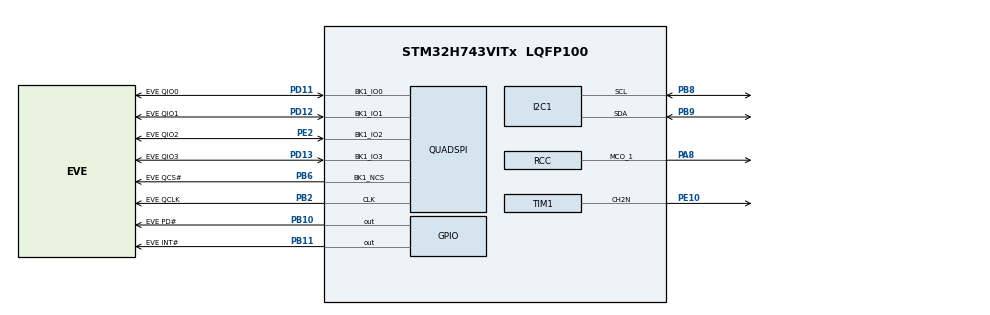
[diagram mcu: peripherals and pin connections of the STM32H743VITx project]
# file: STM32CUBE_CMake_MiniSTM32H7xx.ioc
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CORTEX_M7.AccessPermission-Cortex_Memory_Protection_Unit_Region0_Settings=MPU_REGION_PRIV_RO
CORTEX_M7.BaseAddress-Cortex_Memory_Protection_Unit_Region0_Settings=0x08000000
CORTEX_M7.Enable-Cortex_Memory_Protection_Unit_Region0_Settings=MPU_REGION_ENABLE
CORTEX_M7.IsCacheable-Cortex_Memory_Protection_Unit_Region0_Settings=MPU_ACCESS_CACHEABLE
CORTEX_M7.MPU_Control=MPU_PRIVILEGED_DEFAULT
CORTEX_M7.Size-Cortex_Memory_Protection_Unit_Region0_Settings=MPU_REGION_SIZE_2MB
CORTEX_M7.TypeExtField-Cortex_Memory_Protection_Unit_Region0_Settings=MPU_TEX_LEVEL1
I2C1.I2C_Fall_Time=10
I2C1.I2C_Rise_Time=100
I2C1.Timing=0xA010151E
Mcu.Family=STM32H7
Mcu.Name=STM32H743VITx
Mcu.Package=LQFP100
NVIC.PriorityGroup=NVIC_PRIORITYGROUP_4
NVIC.TIM16_IRQn=true\:0\:0\:false\:false\:true\:true\:true\:true
PA13\ (JTMS/SWDIO).Mode=Trace_Asynchronous_SW
PA13\ (JTMS/SWDIO).Signal=DEBUG_JTMS-SWDIO
PA14\ (JTCK/SWCLK).Mode=Trace_Asynchronous_SW
PA14\ (JTCK/SWCLK).Signal=DEBUG_JTCK-SWCLK
PA8.Mode=Clock-out-1
PA8.Signal=RCC_MCO_1
PB10.GPIO_Label=EVE PD\#
PB10.Signal=GPIO_Output
PB11.GPIO_Label=EVE INT\#
PB11.Signal=GPIO_Output
PB2.GPIO_Label=EVE QCLK
PB2.GPIO_PuPd=GPIO_NOPULL
PB2.GPIO_Speed=GPIO_SPEED_FREQ_VERY_HIGH
PB2.Mode=Single Bank 1
PB2.Signal=QUADSPI_CLK
PB3\ (JTDO/TRACESWO).Mode=Trace_Asynchronous_SW
PB3\ (JTDO/TRACESWO).Signal=DEBUG_JTDO-SWO
PB6.GPIO_FM6=SYSCFG_PMCR_I2C_PB6_FMP
PB6.GPIO_Label=EVE QCS\#
PB6.GPIO_PuPd=GPIO_NOPULL
PB6.GPIO_Speed=GPIO_SPEED_FREQ_VERY_HIGH
PB6.Mode=Single Bank 1
PB6.Signal=QUADSPI_BK1_NCS
PB8.GPIO_Pu=GPIO_PULLUP
PB8.Mode=I2C
PB8.Signal=I2C1_SCL
PB9.GPIO_Pu=GPIO_PULLUP
PB9.Mode=I2C
PB9.Signal=I2C1_SDA
PC14-OSC32_IN\ (OSC32_IN).Mode=LSE-External-Oscillator
PC14-OSC32_IN\ (OSC32_IN).Signal=RCC_OSC32_IN
PC15-OSC32_OUT\ (OSC32_OUT).Mode=LSE-External-Oscillator
PC15-OSC32_OUT\ (OSC32_OUT).Signal=RCC_OSC32_OUT
PC7.Signal=DCMI_D1
PD11.GPIO_Label=EVE QIO0
PD11.GPIO_PuPd=GPIO_NOPULL
PD11.GPIO_Speed=GPIO_SPEED_FREQ_VERY_HIGH
PD11.Mode=Single Bank 1
PD11.Signal=QUADSPI_BK1_IO0
PD12.GPIO_Label=EVE QIO1
PD12.GPIO_PuPd=GPIO_NOPULL
PD12.GPIO_Speed=GPIO_SPEED_FREQ_VERY_HIGH
PD12.Mode=Single Bank 1
PD12.Signal=QUADSPI_BK1_IO1
PD13.GPIO_Label=EVE QIO3
PD13.GPIO_PuPd=GPIO_NOPULL
PD13.GPIO_Speed=GPIO_SPEED_FREQ_VERY_HIGH
PD13.Mode=Single Bank 1
PD13.Signal=QUADSPI_BK1_IO3
PE10.Mode=PWM Generation2 CH2N
PE10.Signal=TIM1_CH2N
PE2.GPIO_Label=EVE QIO2
PE2.GPIO_PuPd=GPIO_NOPULL
PE2.GPIO_Speed=GPIO_SPEED_FREQ_VERY_HIGH
PE2.Mode=Single Bank 1
PE2.Signal=QUADSPI_BK1_IO2
PH0-OSC_IN\ (PH0).Mode=HSE-External-Oscillator
PH0-OSC_IN\ (PH0).Signal=RCC_OSC_IN
PH1-OSC_OUT\ (PH1).Mode=HSE-External-Oscillator
PH1-OSC_OUT\ (PH1).Signal=RCC_OSC_OUT
ProjectManager.HeapSize=0x2000
ProjectManager.StackSize=0x14000
ProjectManager.TargetToolchain=CMake
QUADSPI.ChipSelectHighTime=QSPI_CS_HIGH_TIME_3_CYCLE
QUADSPI.ClockMode=QSPI_CLOCK_MODE_0
QUADSPI.ClockPrescaler=2-1
QUADSPI.FlashSize=32-1
QUADSPI.SampleShifting=QSPI_SAMPLE_SHIFTING_HALFCYCLE
RCC.ADCCLockSelection=RCC_ADCCLKSOURCE_PLL2
RCC.ADCFreq_Value=50390625
RCC.APB1Freq_Value=60000000
RCC.APB2Freq_Value=120000000
RCC.APB3Freq_Value=120000000
RCC.APB4Freq_Value=120000000
RCC.CECCLockSelection=RCC_CECCLKSOURCE_LSI
RCC.CKPERSourceSelection=RCC_CLKPSOURCE_HSI
RCC.CSI_VALUE=4000000
RCC.CortexFreq_Value=240000000
RCC.Cortex_Div=SYSTICK_CLKSOURCE_HCLK
RCC.Cortex_DivARG=SystemCoreClock/1000
RCC.D2PPRE1=RCC_APB1_DIV2
RCC.DFSDMCLockSelection=RCC_DFSDM1CLKSOURCE_D2PCLK1
RCC.DIVM1=5
RCC.DIVM2=32
RCC.DIVM3=2
RCC.DIVN1=96
RCC.DIVN2=129
RCC.DIVN3=12
RCC.DIVP2=2
RCC.DIVP3=5
RCC.DIVQ1=4
RCC.DIVQ2=2
RCC.DIVQ3=3
RCC.DIVR1=4
RCC.DIVR2=2
RCC.DIVR3=2
RCC.DSICLockSelection=RCC_DSICLKSOURCE_PHY
RCC.DSIPHY_Div=8
RCC.DSITX_Div=4
RCC.DSI_PHY_VALUE=12288000
RCC.EXTERNAL_CLOCK_VALUE=12288000
RCC.FDCANCLockSelection=RCC_FDCANCLKSOURCE_PLL
RCC.FMCCLockSelection=RCC_FMCCLKSOURCE_D1HCLK
RCC.HCLKFreq_Value=120000000
RCC.HPRE=RCC_HCLK_DIV2
RCC.HSE_VALUE=25000000
RCC.HSIDiv=RCC_PLLSAIDIVR_1
RCC.HSI_VALUE=64000000
RCC.I2C123CLockSelection=RCC_I2C123CLKSOURCE_D2PCLK1
RCC.I2C4CLockSelection=RCC_I2C4CLKSOURCE_D3PCLK1
RCC.LPTIM1CLockSelection=RCC_LPTIM1CLKSOURCE_D2PCLK1
RCC.LPTIM2CLockSelection=RCC_LPTIM2CLKSOURCE_D3PCLK1
RCC.LPTIM345CLockSelection=RCC_LPTIM345CLKSOURCE_D3PCLK1
RCC.LPUART1CLockSelection=RCC_LPUART1CLKSOURCE_D3PCLK1
RCC.PLL3FRACN=0
RCC.PLLDSIDev=2
RCC.PLLDSIIDF=DSI_PLL_IN_DIV1
RCC.PLLDSIMult=2
RCC.PLLDSINDIV=20
RCC.PLLDSIODF=DSI_PLL_OUT_DIV1
RCC.PLLFRACN=0
RCC.PLLSourceVirtual=RCC_PLLSOURCE_HSE
RCC.QSPICLockSelection=RCC_QSPICLKSOURCE_D1HCLK
RCC.RC48_VALUE=48000000
RCC.RCC_MCO1Source=RCC_MCO1SOURCE_HSI48
RCC.RCC_MCO2Source=RCC_MCO2SOURCE_SYSCLK
RCC.RCC_MCODiv1=RCC_MCODIV_4
RCC.RCC_MCODiv2=RCC_MCODIV_1
RCC.RCC_RTC_Clock_Source_FROM_HSE=RCC_RTCCLKSOURCE_HSE_DIV2
RCC.RNGCLockSelection=RCC_RNGCLKSOURCE_HSI48
RCC.SAI1CLockSelection=RCC_SAI1CLKSOURCE_PLL
RCC.SAI23CLockSelection=RCC_SAI23CLKSOURCE_PLL
RCC.SAI4ACLockSelection=RCC_SAI4ACLKSOURCE_PLL
RCC.SAI4BCLockSelection=RCC_SAI4BCLKSOURCE_PLL
RCC.SPDIFCLockSelection=RCC_SPDIFRXCLKSOURCE_PLL
RCC.SPI123CLockSelection=RCC_SPI123CLKSOURCE_PLL
RCC.SPI6CLockSelection=RCC_SPI6CLKSOURCE_D3PCLK1
RCC.SWPCLockSelection=RCC_SWPMI1CLKSOURCE_D2PCLK1
RCC.SYSCLKFreq_VALUE=240000000
RCC.SYSCLKSource=RCC_SYSCLKSOURCE_PLLCLK
RCC.Spi45ClockSelection=RCC_SPI45CLKSOURCE_PLL3
RCC.SupplySource=PWR_LDO_SUPPLY
RCC.USART16CLockSelection=RCC_USART16CLKSOURCE_D2PCLK2
RCC.USART234578CLockSelection=RCC_USART234578CLKSOURCE_D2PCLK1
RCC.USBCLockSelection=RCC_USBCLKSOURCE_PLL3
RCC.USBFreq_Value=50000000
TIM1.Channel-PWM\ Generation2\ CH2N=TIM_CHANNEL_2
TIM16.Period=100-1
TIM16.Prescaler=120-1
VP_MEMORYMAP_VS_MEMORYMAP.Mode=CurAppReg
VP_RTC_VS_RTC_Activate.Mode=RTC_Enabled
VP_TIM16_VS_ClockSourceINT.Mode=Enable_Timer
board=custom

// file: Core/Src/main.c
/* USER CODE BEGIN Header */
/**
  ******************************************************************************
  * @file           : main.c
  * @brief          : Main program body
  ******************************************************************************
  * @attention
  *
  * Copyright (c) 2026 STMicroelectronics.
  * All rights reserved.
  *
  * This software is licensed under terms that can be found in the LICENSE file
  * in the root directory of this software component.
  * If no LICENSE file comes with this software, it is provided AS-IS.
  *
  ******************************************************************************
  */
/* USER CODE END Header */
#include "main.h"
#include "i2c.h"
#include "rtc.h"
#include "tim.h"
#include "gpio.h"

/* USER CODE BEGIN Includes */

#include "quadspi.h"

/* Include the example interface and associated function prototypes. */
#include "eve_example.h"

/* USER CODE END Includes */

void SystemClock_Config(void);
static void MPU_Config(void);

/* USER CODE BEGIN 0 */

/**
 * @brief Functions used to store calibration data in file.
   @details Currently not used.
 */
//@{
int8_t platform_calib_init(void)
{
    return 1;
}

int8_t platform_calib_write(struct touchscreen_calibration *calib)
{
    return 0;
}

int8_t platform_calib_read(struct touchscreen_calibration *calib)
{
    return -1;
}
//@}

/* USER CODE END 0 */

int main(void)
{

  /* MPU Configuration--------------------------------------------------------*/
  MPU_Config();

  /* MCU Configuration--------------------------------------------------------*/

  /* Reset of all peripherals, Initializes the Flash interface and the Systick. */
  HAL_Init();

  /* Configure the system clock */
  SystemClock_Config();

  /* Initialize all configured peripherals */
  MX_GPIO_Init();
  MX_RTC_Init();
  MX_I2C1_Init();
  MX_TIM16_Init();
  MX_TIM1_Init();
  /* USER CODE BEGIN 2 */
  MX_QUADSPI_Init();

  /* Start example code */
  eve_example();

  /* USER CODE END 2 */

  /* Infinite loop */
  while (1)
  {

  }
}

void SystemClock_Config(void)
{
  RCC_OscInitTypeDef RCC_OscInitStruct = {0};
  RCC_ClkInitTypeDef RCC_ClkInitStruct = {0};

  /** Supply configuration update enable
  */
  HAL_PWREx_ConfigSupply(PWR_LDO_SUPPLY);

  /** Configure the main internal regulator output voltage
  */
  __HAL_PWR_VOLTAGESCALING_CONFIG(PWR_REGULATOR_VOLTAGE_SCALE2);

  while(!__HAL_PWR_GET_FLAG(PWR_FLAG_VOSRDY)) {}

  /** Initializes the RCC Oscillators according to the specified parameters
  * in the RCC_OscInitTypeDef structure.
  */
  RCC_OscInitStruct.OscillatorType = RCC_OSCILLATORTYPE_HSI48|RCC_OSCILLATORTYPE_LSI
                              |RCC_OSCILLATORTYPE_HSE;
  RCC_OscInitStruct.HSEState = RCC_HSE_ON;
  RCC_OscInitStruct.LSIState = RCC_LSI_ON;
  RCC_OscInitStruct.HSI48State = RCC_HSI48_ON;
  RCC_OscInitStruct.PLL.PLLState = RCC_PLL_ON;
  RCC_OscInitStruct.PLL.PLLSource = RCC_PLLSOURCE_HSE;
  RCC_OscInitStruct.PLL.PLLM = 5;
  RCC_OscInitStruct.PLL.PLLN = 96;
  RCC_OscInitStruct.PLL.PLLP = 2;
  RCC_OscInitStruct.PLL.PLLQ = 4;
  RCC_OscInitStruct.PLL.PLLR = 4;
  RCC_OscInitStruct.PLL.PLLRGE = RCC_PLL1VCIRANGE_2;
  RCC_OscInitStruct.PLL.PLLVCOSEL = RCC_PLL1VCOWIDE;
  RCC_OscInitStruct.PLL.PLLFRACN = 0;
  if (HAL_RCC_OscConfig(&RCC_OscInitStruct) != HAL_OK)
  {
    Error_Handler();
  }

  /** Initializes the CPU, AHB and APB buses clocks
  */
  RCC_ClkInitStruct.ClockType = RCC_CLOCKTYPE_HCLK|RCC_CLOCKTYPE_SYSCLK
                              |RCC_CLOCKTYPE_PCLK1|RCC_CLOCKTYPE_PCLK2
                              |RCC_CLOCKTYPE_D3PCLK1|RCC_CLOCKTYPE_D1PCLK1;
  RCC_ClkInitStruct.SYSCLKSource = RCC_SYSCLKSOURCE_PLLCLK;
  RCC_ClkInitStruct.SYSCLKDivider = RCC_SYSCLK_DIV1;
  RCC_ClkInitStruct.AHBCLKDivider = RCC_HCLK_DIV2;
  RCC_ClkInitStruct.APB3CLKDivider = RCC_APB3_DIV1;
  RCC_ClkInitStruct.APB1CLKDivider = RCC_APB1_DIV2;
  RCC_ClkInitStruct.APB2CLKDivider = RCC_APB2_DIV1;
  RCC_ClkInitStruct.APB4CLKDivider = RCC_APB4_DIV1;

  if (HAL_RCC_ClockConfig(&RCC_ClkInitStruct, FLASH_LATENCY_2) != HAL_OK)
  {
    Error_Handler();
  }
  HAL_RCC_MCOConfig(RCC_MCO1, RCC_MCO1SOURCE_HSI48, RCC_MCODIV_4);
}

 /* MPU Configuration */

void MPU_Config(void)
{
  MPU_Region_InitTypeDef MPU_InitStruct = {0};

  /* Disables the MPU */
  HAL_MPU_Disable();

  /** Initializes and configures the Region and the memory to be protected
  */
  MPU_InitStruct.Enable = MPU_REGION_ENABLE;
  MPU_InitStruct.Number = MPU_REGION_NUMBER0;
  MPU_InitStruct.BaseAddress = 0x08000000;
  MPU_InitStruct.Size = MPU_REGION_SIZE_2MB;
  MPU_InitStruct.SubRegionDisable = 0x0;
  MPU_InitStruct.TypeExtField = MPU_TEX_LEVEL1;
  MPU_InitStruct.AccessPermission = MPU_REGION_PRIV_RO;
  MPU_InitStruct.DisableExec = MPU_INSTRUCTION_ACCESS_ENABLE;
  MPU_InitStruct.IsShareable = MPU_ACCESS_NOT_SHAREABLE;
  MPU_InitStruct.IsCacheable = MPU_ACCESS_CACHEABLE;
  MPU_InitStruct.IsBufferable = MPU_ACCESS_NOT_BUFFERABLE;

  HAL_MPU_ConfigRegion(&MPU_InitStruct);
  /* Enables the MPU */
  HAL_MPU_Enable(MPU_PRIVILEGED_DEFAULT);

}

void Error_Handler(void)
{
  __disable_irq();
  while (1)
  {
  }
}
